# Modem_INTC register map
Vendor: Texas Instruments
Peripheral module from a debugger description file (folder omap36xx).
Registers are 32-bit, access per field, reset 0x0 unless marked. A register's access mark holds for its fields unless they carry their own. Offsets are as the file gives them; lines under a group give offsets from that group; [hi:lo] are bit positions; {n}, {i} and the like mark numbered series; 'fields as' and 'values as' point back to an identical list; <NAME> marks a mode.

## Modem_INTC
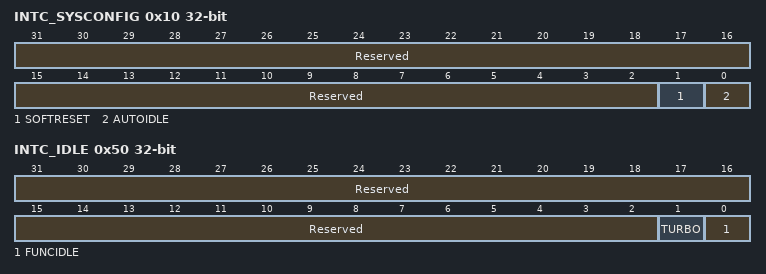
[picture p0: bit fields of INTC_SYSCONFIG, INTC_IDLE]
0x10 INTC_SYSCONFIG — This register controls various parameters of the module interface.
  [31:2] Reserved ro — Write 0s for future compatibility. Read returns reset value.
  [1] SOFTRESET rw — Software reset. Set this bit to trigger a module reset. The bit is automatically reset by the hardware. Read returns 0.
    0=No functional effect; 1=The module is reset
  [0] AUTOIDLE rw — Internal interface clock gating strategy
    0=Interface clock is free-running; 1=Automatic interface clock gating strategy is applied, based on the interface bus activity
0x50 INTC_IDLE — This register controls the functional clock auto-idle and the synchronizer clock auto-gating.
  [31:2] Reserved ro — Write 0s for future compatibility. Read returns reset value.
  [1] TURBO rw — Input synchronizer clock auto-gating
    0=Input synchronizer clock is free-running (default); 1=Input synchronizer clock is auto-gated based on interrupt input activity
  [0] FUNCIDLE rw — Functional clock idle mode
    0=Functional clock gating strategy is applied (default); 1=Functional clock is free-running
